# StarFive VisionFive 2 v1.3B register map
File version: 0.1
Registers are 32-bit, read-write, reset 0x0 unless marked. A register's access mark holds for its fields unless they carry their own. Offsets are from the block's base; [hi:lo] are bit positions; {n}, {i} and the like mark numbered series; 'fields as' and 'values as' point back to an identical list.

## sys_pinctrl — From starfive,jh7110-sys-pinctrl, peripheral generator
Base 0x13040000
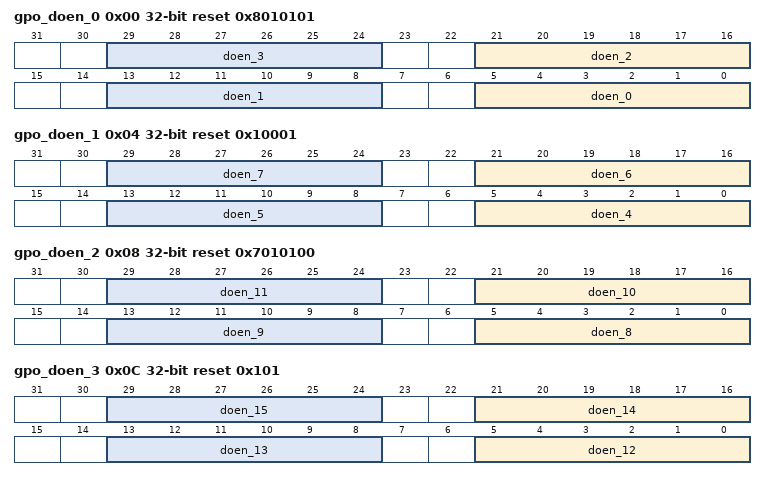
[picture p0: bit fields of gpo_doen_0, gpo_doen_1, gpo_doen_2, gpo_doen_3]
0x00 gpo_doen_0 reset 0x8010101 — SYS IOMUX CFG SAIF SYSCFG FMUX 0 DOEN
  [8n+5:8n] doen_{n} (n=0..3) — The selected OEN signal for GPIO{n}. The register value indicates the selected GPIO (Output Enable) OEN index from GPIO OEN list 0-49. See Table 2-41: GPIO OEN List for SYS_IOMUX (on page 97) for more information.
0x04 gpo_doen_1 reset 0x10001 — SYS IOMUX CFG SAIF SYSCFG FMUX 1 DOEN
  [8n-27:8n-32] doen_{n} (n=4..7) — The selected OEN signal for GPIO{n}. The register value indicates the selected GPIO (Output Enable) OEN index from GPIO OEN list 0-49. See Table 2-41: GPIO OEN List for SYS_IOMUX (on page 97) for more information.
0x08 gpo_doen_2 reset 0x7010100 — SYS IOMUX CFG SAIF SYSCFG FMUX 2 DOEN
  [8n-59:8n-64] doen_{n} (n=8..11) — The selected OEN signal for GPIO{n}. The register value indicates the selected GPIO (Output Enable) OEN index from GPIO OEN list 0-49. See Table 2-41: GPIO OEN List for SYS_IOMUX (on page 97) for more information.
0x0C gpo_doen_3 reset 0x101 — SYS IOMUX CFG SAIF SYSCFG FMUX 3 DOEN
  [8n-91:8n-96] doen_{n} (n=12..15) — The selected OEN signal for GPIO{n}. The register value indicates the selected GPIO (Output Enable) OEN index from GPIO OEN list 0-49. See Table 2-41: GPIO OEN List for SYS_IOMUX (on page 97) for more information.
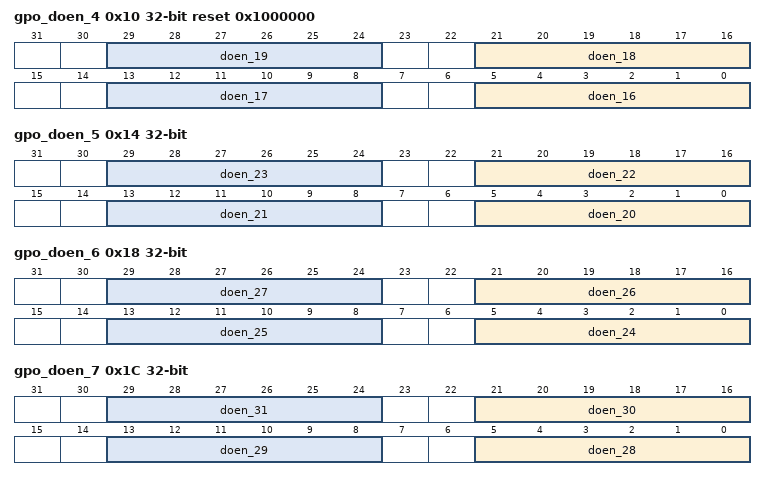
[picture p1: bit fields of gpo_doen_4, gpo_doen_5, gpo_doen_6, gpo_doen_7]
0x10 gpo_doen_4 reset 0x1000000 — SYS IOMUX CFG SAIF SYSCFG FMUX 4 DOEN
  [8n-123:8n-128] doen_{n} (n=16..19) — The selected OEN signal for GPIO{n}. The register value indicates the selected GPIO (Output Enable) OEN index from GPIO OEN list 0-49. See Table 2-41: GPIO OEN List for SYS_IOMUX (on page 97) for more information.
0x14 gpo_doen_5 — SYS IOMUX CFG SAIF SYSCFG FMUX 5 DOEN
  [8n-155:8n-160] doen_{n} (n=20..23) — The selected OEN signal for GPIO{n}. The register value indicates the selected GPIO (Output Enable) OEN index from GPIO OEN list 0-49. See Table 2-41: GPIO OEN List for SYS_IOMUX (on page 97) for more information.
0x18 gpo_doen_6 — SYS IOMUX CFG SAIF SYSCFG FMUX 6 DOEN
  [8n-187:8n-192] doen_{n} (n=24..27) — The selected OEN signal for GPIO{n}. The register value indicates the selected GPIO (Output Enable) OEN index from GPIO OEN list 0-49. See Table 2-41: GPIO OEN List for SYS_IOMUX (on page 97) for more information.
0x1C gpo_doen_7 — SYS IOMUX CFG SAIF SYSCFG FMUX 7 DOEN
  [8n-219:8n-224] doen_{n} (n=28..31) — The selected OEN signal for GPIO{n}. The register value indicates the selected GPIO (Output Enable) OEN index from GPIO OEN list 0-49. See Table 2-41: GPIO OEN List for SYS_IOMUX (on page 97) for more information.
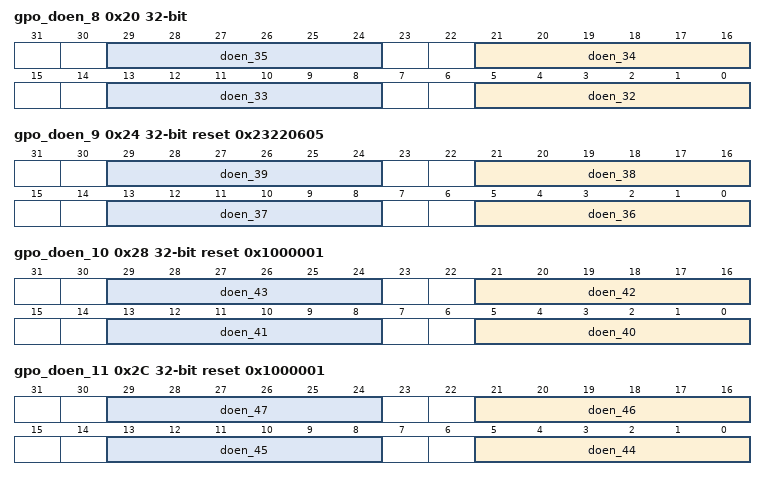
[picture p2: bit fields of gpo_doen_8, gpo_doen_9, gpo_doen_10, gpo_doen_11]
0x20 gpo_doen_8 — SYS IOMUX CFG SAIF SYSCFG FMUX 8 DOEN
  [8n-251:8n-256] doen_{n} (n=32..35) — The selected OEN signal for GPIO{n}. The register value indicates the selected GPIO (Output Enable) OEN index from GPIO OEN list 0-49. See Table 2-41: GPIO OEN List for SYS_IOMUX (on page 97) for more information.
0x24 gpo_doen_9 reset 0x23220605 — SYS IOMUX CFG SAIF SYSCFG FMUX 9 DOEN
  [8n-283:8n-288] doen_{n} (n=36..39) — The selected OEN signal for GPIO{n}. The register value indicates the selected GPIO (Output Enable) OEN index from GPIO OEN list 0-49. See Table 2-41: GPIO OEN List for SYS_IOMUX (on page 97) for more information.
0x28 gpo_doen_10 reset 0x1000001 — SYS IOMUX CFG SAIF SYSCFG FMUX 10 DOEN
  [8n-315:8n-320] doen_{n} (n=40..43) — The selected OEN signal for GPIO{n}. The register value indicates the selected GPIO (Output Enable) OEN index from GPIO OEN list 0-49. See Table 2-41: GPIO OEN List for SYS_IOMUX (on page 97) for more information.
0x2C gpo_doen_11 reset 0x1000001 — SYS IOMUX CFG SAIF SYSCFG FMUX 11 DOEN
  [8n-347:8n-352] doen_{n} (n=44..47) — The selected OEN signal for GPIO{n}. The register value indicates the selected GPIO (Output Enable) OEN index from GPIO OEN list 0-49. See Table 2-41: GPIO OEN List for SYS_IOMUX (on page 97) for more information.
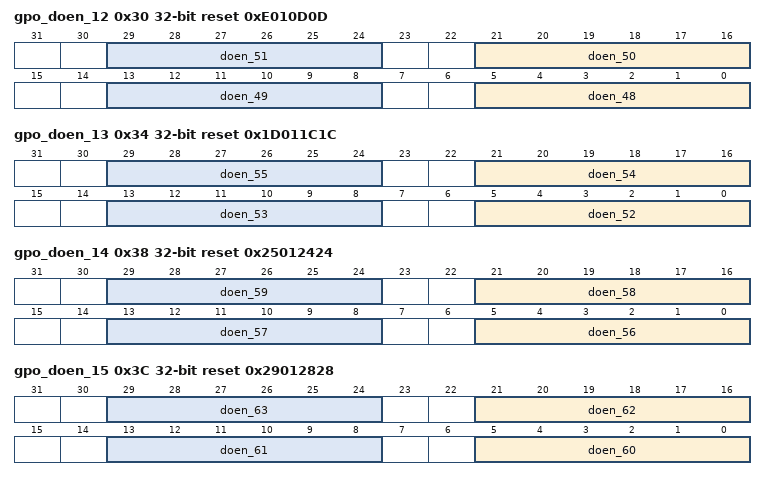
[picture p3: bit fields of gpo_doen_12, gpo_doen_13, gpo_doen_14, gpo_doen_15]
0x30 gpo_doen_12 reset 0xE010D0D — SYS IOMUX CFG SAIF SYSCFG FMUX 12 DOEN
  [8n-379:8n-384] doen_{n} (n=48..51) — The selected OEN signal for GPIO{n}. The register value indicates the selected GPIO (Output Enable) OEN index from GPIO OEN list 0-49. See Table 2-41: GPIO OEN List for SYS_IOMUX (on page 97) for more information.
0x34 gpo_doen_13 reset 0x1D011C1C — SYS IOMUX CFG SAIF SYSCFG FMUX 13 DOEN
  [8n-411:8n-416] doen_{n} (n=52..55) — The selected OEN signal for GPIO{n}. The register value indicates the selected GPIO (Output Enable) OEN index from GPIO OEN list 0-49. See Table 2-41: GPIO OEN List for SYS_IOMUX (on page 97) for more information.
0x38 gpo_doen_14 reset 0x25012424 — SYS IOMUX CFG SAIF SYSCFG FMUX 14 DOEN
  [8n-443:8n-448] doen_{n} (n=56..59) — The selected OEN signal for GPIO{n}. The register value indicates the selected GPIO (Output Enable) OEN index from GPIO OEN list 0-49. See Table 2-41: GPIO OEN List for SYS_IOMUX (on page 97) for more information.
0x3C gpo_doen_15 reset 0x29012828 — SYS IOMUX CFG SAIF SYSCFG FMUX 15 DOEN
  [8n-475:8n-480] doen_{n} (n=60..63) — The selected OEN signal for GPIO{n}. The register value indicates the selected GPIO (Output Enable) OEN index from GPIO OEN list 0-49. See Table 2-41: GPIO OEN List for SYS_IOMUX (on page 97) for more information.
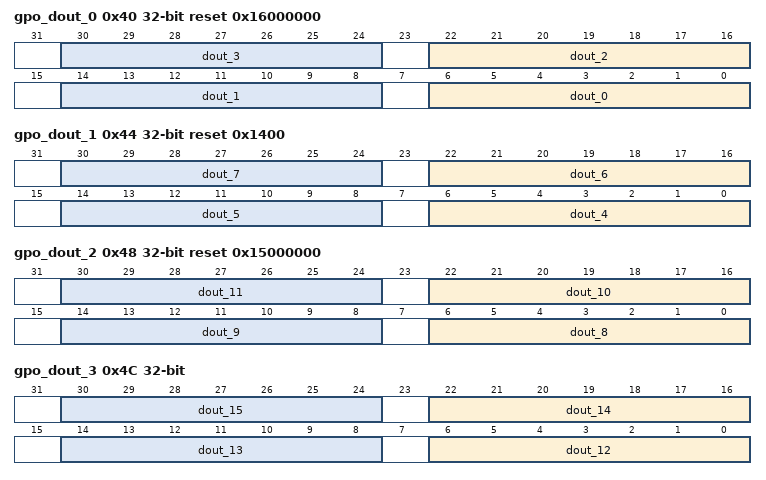
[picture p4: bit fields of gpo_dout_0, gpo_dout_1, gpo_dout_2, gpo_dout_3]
0x40 gpo_dout_0 reset 0x16000000 — SYS IOMUX CFG SAIF SYSCFG FMUX GPIO 0-3 DOUT
  [8n+6:8n] dout_{n} (n=0..3) — The selected output signal for GPIO{n}. The register value indicates the selected GPIO output index signal index from GPIO output signal list 0-107. See Table 2-41: GPIO OEN List for SYS_IOMUX (on page 97) for more information.
0x44 gpo_dout_1 reset 0x1400 — SYS IOMUX CFG SAIF SYSCFG FMUX GPIO 4-7 DOUT
  [8n-26:8n-32] dout_{n} (n=4..7) — The selected output signal for GPIO{n}. The register value indicates the selected GPIO output index signal index from GPIO output signal list 0-107. See Table 2-41: GPIO OEN List for SYS_IOMUX (on page 97) for more information.
0x48 gpo_dout_2 reset 0x15000000 — SYS IOMUX CFG SAIF SYSCFG FMUX GPIO 8-11 DOUT
  [8n-58:8n-64] dout_{n} (n=8..11) — The selected output signal for GPIO{n}. The register value indicates the selected GPIO output index signal index from GPIO output signal list 0-107. See Table 2-41: GPIO OEN List for SYS_IOMUX (on page 97) for more information.
0x4C gpo_dout_3 — SYS IOMUX CFG SAIF SYSCFG FMUX GPIO 12-15 DOUT
  [8n-90:8n-96] dout_{n} (n=12..15) — The selected output signal for GPIO{n}. The register value indicates the selected GPIO output index signal index from GPIO output signal list 0-107. See Table 2-41: GPIO OEN List for SYS_IOMUX (on page 97) for more information.
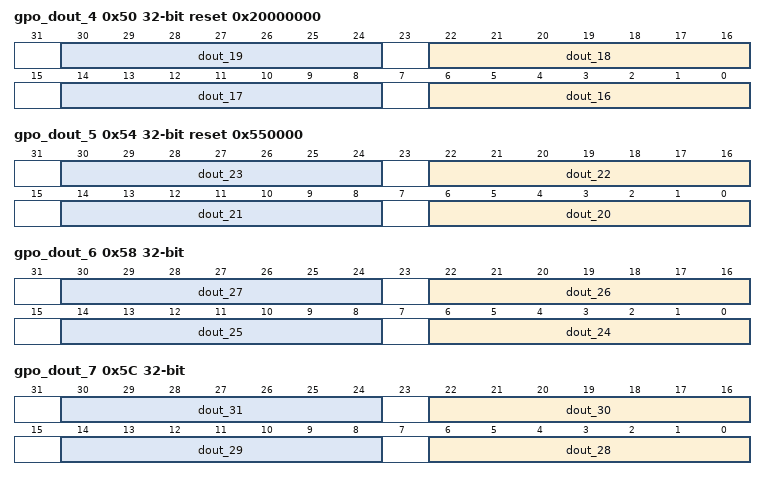
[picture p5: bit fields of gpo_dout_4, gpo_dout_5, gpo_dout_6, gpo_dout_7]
0x50 gpo_dout_4 reset 0x20000000 — SYS IOMUX CFG SAIF SYSCFG FMUX GPIO 16-19 DOUT
  [8n-122:8n-128] dout_{n} (n=16..19) — The selected output signal for GPIO{n}. The register value indicates the selected GPIO output index signal index from GPIO output signal list 0-107. See Table 2-41: GPIO OEN List for SYS_IOMUX (on page 97) for more information.
0x54 gpo_dout_5 reset 0x550000 — SYS IOMUX CFG SAIF SYSCFG FMUX GPIO 20-23 DOUT
  [8n-154:8n-160] dout_{n} (n=20..23) — The selected output signal for GPIO{n}. The register value indicates the selected GPIO output index signal index from GPIO output signal list 0-107. See Table 2-41: GPIO OEN List for SYS_IOMUX (on page 97) for more information.
0x58 gpo_dout_6 — SYS IOMUX CFG SAIF SYSCFG FMUX GPIO 24-27 DOUT
  [8n-186:8n-192] dout_{n} (n=24..27) — The selected output signal for GPIO{n}. The register value indicates the selected GPIO output index signal index from GPIO output signal list 0-107. See Table 2-41: GPIO OEN List for SYS_IOMUX (on page 97) for more information.
0x5C gpo_dout_7 — SYS IOMUX CFG SAIF SYSCFG FMUX GPIO 28-31 DOUT
  [8n-218:8n-224] dout_{n} (n=28..31) — The selected output signal for GPIO{n}. The register value indicates the selected GPIO output index signal index from GPIO output signal list 0-107. See Table 2-41: GPIO OEN List for SYS_IOMUX (on page 97) for more information.
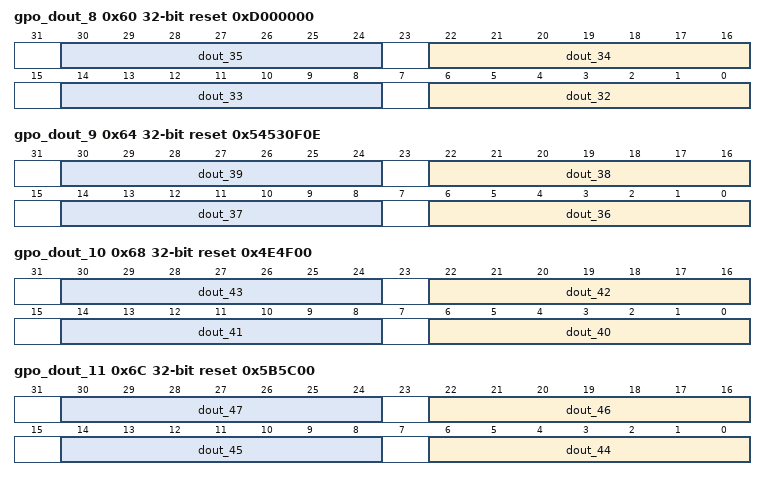
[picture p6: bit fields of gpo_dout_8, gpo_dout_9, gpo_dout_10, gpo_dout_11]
0x60 gpo_dout_8 reset 0xD000000 — SYS IOMUX CFG SAIF SYSCFG FMUX GPIO 32-35 DOUT
  [8n-250:8n-256] dout_{n} (n=32..35) — The selected output signal for GPIO{n}. The register value indicates the selected GPIO output index signal index from GPIO output signal list 0-107. See Table 2-41: GPIO OEN List for SYS_IOMUX (on page 97) for more information.
0x64 gpo_dout_9 reset 0x54530F0E — SYS IOMUX CFG SAIF SYSCFG FMUX GPIO 36-39 DOUT
  [8n-282:8n-288] dout_{n} (n=36..39) — The selected output signal for GPIO{n}. The register value indicates the selected GPIO output index signal index from GPIO output signal list 0-107. See Table 2-41: GPIO OEN List for SYS_IOMUX (on page 97) for more information.
0x68 gpo_dout_10 reset 0x4E4F00 — SYS IOMUX CFG SAIF SYSCFG FMUX GPIO 40-43 DOUT
  [8n-314:8n-320] dout_{n} (n=40..43) — The selected output signal for GPIO{n}. The register value indicates the selected GPIO output index signal index from GPIO output signal list 0-107. See Table 2-41: GPIO OEN List for SYS_IOMUX (on page 97) for more information.
0x6C gpo_dout_11 reset 0x5B5C00 — SYS IOMUX CFG SAIF SYSCFG FMUX GPIO 44-47 DOUT
  [8n-346:8n-352] dout_{n} (n=44..47) — The selected output signal for GPIO{n}. The register value indicates the selected GPIO output index signal index from GPIO output signal list 0-107. See Table 2-41: GPIO OEN List for SYS_IOMUX (on page 97) for more information.
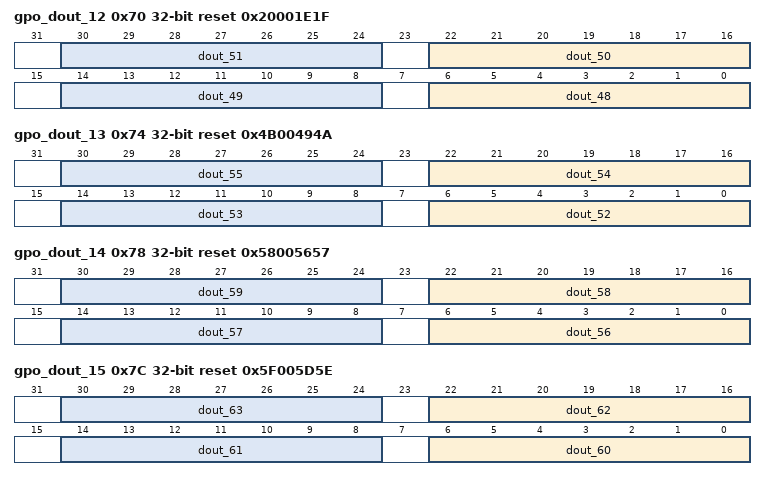
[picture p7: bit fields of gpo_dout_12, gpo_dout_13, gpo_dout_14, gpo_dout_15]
0x70 gpo_dout_12 reset 0x20001E1F — SYS IOMUX CFG SAIF SYSCFG FMUX GPIO 48-51 DOUT
  [8n-378:8n-384] dout_{n} (n=48..51) — The selected output signal for GPIO{n}. The register value indicates the selected GPIO output index signal index from GPIO output signal list 0-107. See Table 2-41: GPIO OEN List for SYS_IOMUX (on page 97) for more information.
0x74 gpo_dout_13 reset 0x4B00494A — SYS IOMUX CFG SAIF SYSCFG FMUX GPIO 52-55 DOUT
  [8n-410:8n-416] dout_{n} (n=52..55) — The selected output signal for GPIO{n}. The register value indicates the selected GPIO output index signal index from GPIO output signal list 0-107. See Table 2-41: GPIO OEN List for SYS_IOMUX (on page 97) for more information.
0x78 gpo_dout_14 reset 0x58005657 — SYS IOMUX CFG SAIF SYSCFG FMUX GPIO 56-59 DOUT
  [8n-442:8n-448] dout_{n} (n=56..59) — The selected output signal for GPIO{n}. The register value indicates the selected GPIO output index signal index from GPIO output signal list 0-107. See Table 2-41: GPIO OEN List for SYS_IOMUX (on page 97) for more information.
0x7C gpo_dout_15 reset 0x5F005D5E — SYS IOMUX CFG SAIF SYSCFG FMUX GPIO 60-63 DOUT
  [8n-474:8n-480] dout_{n} (n=60..63) — The selected output signal for GPIO{n}. The register value indicates the selected GPIO output index signal index from GPIO output signal list 0-107. See Table 2-41: GPIO OEN List for SYS_IOMUX (on page 97) for more information.
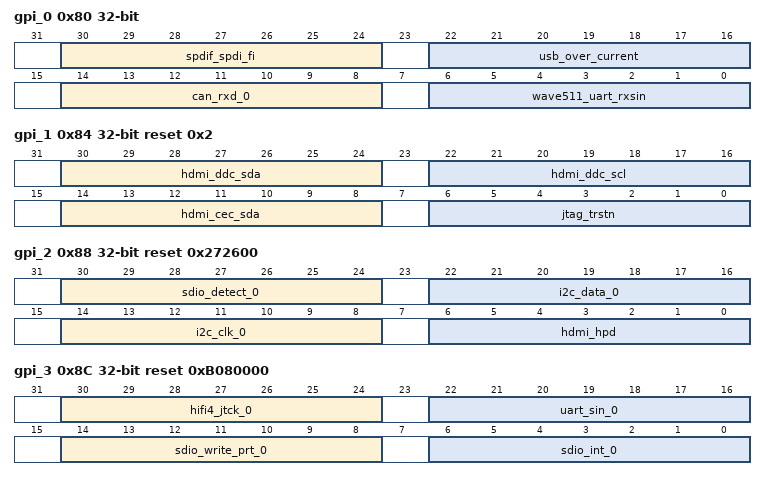
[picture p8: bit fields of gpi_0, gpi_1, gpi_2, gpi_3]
0x80 gpi_0 — SYS IOMUX CFG SAIF SYSCFG FMUX GPIO GPI 0 - The register can be used to configure the selected GPIO connector number for input signals. The signal name is indicated in the "Name" column of the following table per StarFive naming conventions. For example, name "u0_WAVE511_i_uart_rxsin_cfg" indicates the corresponding input signal is "u0_WAVE511.i_uart_rxsin". See GPIO Input Signals (on page 107) for a complete list of the input GPIO signals.
  [30:24] spdif_spdi_fi — The register value indicates the selected GPIO number + 2 (GPIO2 - GPIO63, GPIO0 and GPIO1 are not available) for the input signal.
  [22:16] usb_over_current — The register value indicates the selected GPIO number + 2 (GPIO2 - GPIO63, GPIO0 and GPIO1 are not available) for the input signal.
  [14:8] can_rxd_0 — The register value indicates the selected GPIO number + 2 (GPIO2 - GPIO63, GPIO0 and GPIO1 are not available) for the input signal.
  [6:0] wave511_uart_rxsin — The register value indicates the selected GPIO number + 2 (GPIO2 - GPIO63, GPIO0 and GPIO1 are not available) for the input signal.
0x84 gpi_1 reset 0x2 — SYS IOMUX CFG SAIF SYSCFG FMUX GPIO GPI 4 - The register can be used to configure the selected GPIO connector number for input signals. The signal name is indicated in the "Name" column of the following table per StarFive naming conventions. For example, name "u0_WAVE511_i_uart_rxsin_cfg" indicates the corresponding input signal is "u0_WAVE511.i_uart_rxsin". See GPIO Input Signals (on page 107) for a complete list of the input GPIO signals.
  [30:24] hdmi_ddc_sda — The register value indicates the selected GPIO number + 2 (GPIO2 - GPIO63, GPIO0 and GPIO1 are not available) for the input signal.
  [22:16] hdmi_ddc_scl — The register value indicates the selected GPIO number + 2 (GPIO2 - GPIO63, GPIO0 and GPIO1 are not available) for the input signal.
  [14:8] hdmi_cec_sda — The register value indicates the selected GPIO number + 2 (GPIO2 - GPIO63, GPIO0 and GPIO1 are not available) for the input signal.
  [6:0] jtag_trstn — The register value indicates the selected GPIO number + 2 (GPIO2 - GPIO63, GPIO0 and GPIO1 are not available) for the input signal.
0x88 gpi_2 reset 0x272600 — SYS IOMUX CFG SAIF SYSCFG FMUX GPIO GPI 8 - The register can be used to configure the selected GPIO connector number for input signals. The signal name is indicated in the "Name" column of the following table per StarFive naming conventions. For example, name "u0_WAVE511_i_uart_rxsin_cfg" indicates the corresponding input signal is "u0_WAVE511.i_uart_rxsin". See GPIO Input Signals (on page 107) for a complete list of the input GPIO signals.
  [30:24] sdio_detect_0 — The register value indicates the selected GPIO number + 2 (GPIO2 - GPIO63, GPIO0 and GPIO1 are not available) for the input signal.
  [22:16] i2c_data_0 — The register value indicates the selected GPIO number + 2 (GPIO2 - GPIO63, GPIO0 and GPIO1 are not available) for the input signal.
  [14:8] i2c_clk_0 — The register value indicates the selected GPIO number + 2 (GPIO2 - GPIO63, GPIO0 and GPIO1 are not available) for the input signal.
  [6:0] hdmi_hpd — The register value indicates the selected GPIO number + 2 (GPIO2 - GPIO63, GPIO0 and GPIO1 are not available) for the input signal.
0x8C gpi_3 reset 0xB080000 — SYS IOMUX CFG SAIF SYSCFG FMUX GPIO GPI 12 - The register can be used to configure the selected GPIO connector number for input signals. The signal name is indicated in the "Name" column of the following table per StarFive naming conventions. For example, name "u0_WAVE511_i_uart_rxsin_cfg" indicates the corresponding input signal is "u0_WAVE511.i_uart_rxsin". See GPIO Input Signals (on page 107) for a complete list of the input GPIO signals.
  [30:24] hifi4_jtck_0 — The register value indicates the selected GPIO number + 2 (GPIO2 - GPIO63, GPIO0 and GPIO1 are not available) for the input signal.
  [22:16] uart_sin_0 — The register value indicates the selected GPIO number + 2 (GPIO2 - GPIO63, GPIO0 and GPIO1 are not available) for the input signal.
  [14:8] sdio_write_prt_0 — The register value indicates the selected GPIO number + 2 (GPIO2 - GPIO63, GPIO0 and GPIO1 are not available) for the input signal.
  [6:0] sdio_int_0 — The register value indicates the selected GPIO number + 2 (GPIO2 - GPIO63, GPIO0 and GPIO1 are not available) for the input signal.
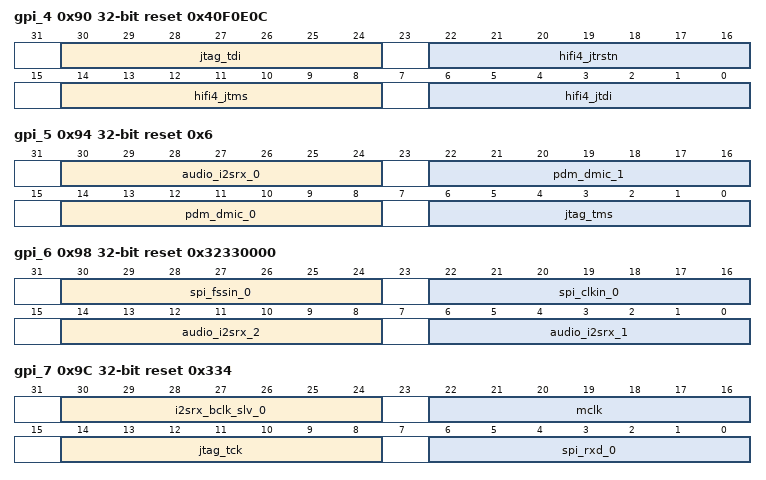
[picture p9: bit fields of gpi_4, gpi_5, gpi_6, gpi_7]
0x90 gpi_4 reset 0x40F0E0C — SYS IOMUX CFG SAIF SYSCFG FMUX GPIO GPI 16 - The register can be used to configure the selected GPIO connector number for input signals. The signal name is indicated in the "Name" column of the following table per StarFive naming conventions. For example, name "u0_WAVE511_i_uart_rxsin_cfg" indicates the corresponding input signal is "u0_WAVE511.i_uart_rxsin". See GPIO Input Signals (on page 107) for a complete list of the input GPIO signals.
  [30:24] jtag_tdi — The register value indicates the selected GPIO number + 2 (GPIO2 - GPIO63, GPIO0 and GPIO1 are not available) for the input signal.
  [22:16] hifi4_jtrstn — The register value indicates the selected GPIO number + 2 (GPIO2 - GPIO63, GPIO0 and GPIO1 are not available) for the input signal.
  [14:8] hifi4_jtms — The register value indicates the selected GPIO number + 2 (GPIO2 - GPIO63, GPIO0 and GPIO1 are not available) for the input signal.
  [6:0] hifi4_jtdi — The register value indicates the selected GPIO number + 2 (GPIO2 - GPIO63, GPIO0 and GPIO1 are not available) for the input signal.
0x94 gpi_5 reset 0x6 — SYS IOMUX CFG SAIF SYSCFG FMUX GPIO GPI 20 - The register can be used to configure the selected GPIO connector number for input signals. The signal name is indicated in the "Name" column of the following table per StarFive naming conventions. For example, name "u0_WAVE511_i_uart_rxsin_cfg" indicates the corresponding input signal is "u0_WAVE511.i_uart_rxsin". See GPIO Input Signals (on page 107) for a complete list of the input GPIO signals.
  [30:24] audio_i2srx_0 — The register value indicates the selected GPIO number + 2 (GPIO2 - GPIO63, GPIO0 and GPIO1 are not available) for the input signal.
  [22:16] pdm_dmic_1 — The register value indicates the selected GPIO number + 2 (GPIO2 - GPIO63, GPIO0 and GPIO1 are not available) for the input signal.
  [14:8] pdm_dmic_0 — The register value indicates the selected GPIO number + 2 (GPIO2 - GPIO63, GPIO0 and GPIO1 are not available) for the input signal.
  [6:0] jtag_tms — The register value indicates the selected GPIO number + 2 (GPIO2 - GPIO63, GPIO0 and GPIO1 are not available) for the input signal.
0x98 gpi_6 reset 0x32330000 — SYS IOMUX CFG SAIF SYSCFG FMUX GPIO GPI 24 - The register can be used to configure the selected GPIO connector number for input signals. The signal name is indicated in the "Name" column of the following table per StarFive naming conventions. For example, name "u0_WAVE511_i_uart_rxsin_cfg" indicates the corresponding input signal is "u0_WAVE511.i_uart_rxsin". See GPIO Input Signals (on page 107) for a complete list of the input GPIO signals.
  [30:24] spi_fssin_0 — The register value indicates the selected GPIO number + 2 (GPIO2 - GPIO63, GPIO0 and GPIO1 are not available) for the input signal.
  [22:16] spi_clkin_0 — The register value indicates the selected GPIO number + 2 (GPIO2 - GPIO63, GPIO0 and GPIO1 are not available) for the input signal.
  [14:8] audio_i2srx_2 — The register value indicates the selected GPIO number + 2 (GPIO2 - GPIO63, GPIO0 and GPIO1 are not available) for the input signal.
  [6:0] audio_i2srx_1 — The register value indicates the selected GPIO number + 2 (GPIO2 - GPIO63, GPIO0 and GPIO1 are not available) for the input signal.
0x9C gpi_7 reset 0x334 — SYS IOMUX CFG SAIF SYSCFG FMUX GPIO GPI 28 - The register can be used to configure the selected GPIO connector number for input signals. The signal name is indicated in the "Name" column of the following table per StarFive naming conventions. For example, name "u0_WAVE511_i_uart_rxsin_cfg" indicates the corresponding input signal is "u0_WAVE511.i_uart_rxsin". See GPIO Input Signals (on page 107) for a complete list of the input GPIO signals.
  [30:24] i2srx_bclk_slv_0 — The register value indicates the selected GPIO number + 2 (GPIO2 - GPIO63, GPIO0 and GPIO1 are not available) for the input signal.
  [22:16] mclk — The register value indicates the selected GPIO number + 2 (GPIO2 - GPIO63, GPIO0 and GPIO1 are not available) for the input signal.
  [14:8] jtag_tck — The register value indicates the selected GPIO number + 2 (GPIO2 - GPIO63, GPIO0 and GPIO1 are not available) for the input signal.
  [6:0] spi_rxd_0 — The register value indicates the selected GPIO number + 2 (GPIO2 - GPIO63, GPIO0 and GPIO1 are not available) for the input signal.
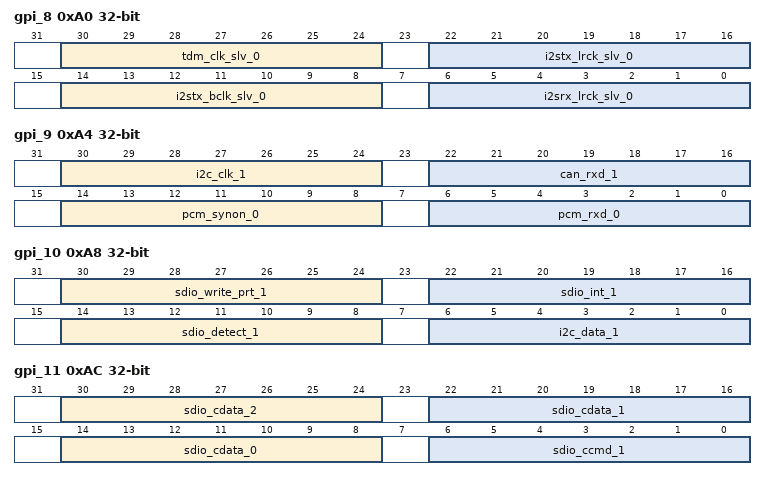
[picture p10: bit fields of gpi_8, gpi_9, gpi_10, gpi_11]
0xA0 gpi_8 — SYS IOMUX CFG SAIF SYSCFG FMUX GPIO GPI 32 - The register can be used to configure the selected GPIO connector number for input signals. The signal name is indicated in the "Name" column of the following table per StarFive naming conventions. For example, name "u0_WAVE511_i_uart_rxsin_cfg" indicates the corresponding input signal is "u0_WAVE511.i_uart_rxsin". See GPIO Input Signals (on page 107) for a complete list of the input GPIO signals.
  [30:24] tdm_clk_slv_0 — The register value indicates the selected GPIO number + 2 (GPIO2 - GPIO63, GPIO0 and GPIO1 are not available) for the input signal.
  [22:16] i2stx_lrck_slv_0 — The register value indicates the selected GPIO number + 2 (GPIO2 - GPIO63, GPIO0 and GPIO1 are not available) for the input signal.
  [14:8] i2stx_bclk_slv_0 — The register value indicates the selected GPIO number + 2 (GPIO2 - GPIO63, GPIO0 and GPIO1 are not available) for the input signal.
  [6:0] i2srx_lrck_slv_0 — The register value indicates the selected GPIO number + 2 (GPIO2 - GPIO63, GPIO0 and GPIO1 are not available) for the input signal.
0xA4 gpi_9 — SYS IOMUX CFG SAIF SYSCFG FMUX GPIO GPI 36 - The register can be used to configure the selected GPIO connector number for input signals. The signal name is indicated in the "Name" column of the following table per StarFive naming conventions. For example, name "u0_WAVE511_i_uart_rxsin_cfg" indicates the corresponding input signal is "u0_WAVE511.i_uart_rxsin". See GPIO Input Signals (on page 107) for a complete list of the input GPIO signals.
  [30:24] i2c_clk_1 — The register value indicates the selected GPIO number + 2 (GPIO2 - GPIO63, GPIO0 and GPIO1 are not available) for the input signal.
  [22:16] can_rxd_1 — The register value indicates the selected GPIO number + 2 (GPIO2 - GPIO63, GPIO0 and GPIO1 are not available) for the input signal.
  [14:8] pcm_synon_0 — The register value indicates the selected GPIO number + 2 (GPIO2 - GPIO63, GPIO0 and GPIO1 are not available) for the input signal.
  [6:0] pcm_rxd_0 — The register value indicates the selected GPIO number + 2 (GPIO2 - GPIO63, GPIO0 and GPIO1 are not available) for the input signal.
0xA8 gpi_10 — SYS IOMUX CFG SAIF SYSCFG FMUX GPIO GPI 40 - The register can be used to configure the selected GPIO connector number for input signals. The signal name is indicated in the "Name" column of the following table per StarFive naming conventions. For example, name "u0_WAVE511_i_uart_rxsin_cfg" indicates the corresponding input signal is "u0_WAVE511.i_uart_rxsin". See GPIO Input Signals (on page 107) for a complete list of the input GPIO signals.
  [30:24] sdio_write_prt_1 — The register value indicates the selected GPIO number + 2 (GPIO2 - GPIO63, GPIO0 and GPIO1 are not available) for the input signal.
  [22:16] sdio_int_1 — The register value indicates the selected GPIO number + 2 (GPIO2 - GPIO63, GPIO0 and GPIO1 are not available) for the input signal.
  [14:8] sdio_detect_1 — The register value indicates the selected GPIO number + 2 (GPIO2 - GPIO63, GPIO0 and GPIO1 are not available) for the input signal.
  [6:0] i2c_data_1 — The register value indicates the selected GPIO number + 2 (GPIO2 - GPIO63, GPIO0 and GPIO1 are not available) for the input signal.
0xAC gpi_11 — SYS IOMUX CFG SAIF SYSCFG FMUX GPIO GPI 44 - The register can be used to configure the selected GPIO connector number for input signals. The signal name is indicated in the "Name" column of the following table per StarFive naming conventions. For example, name "u0_WAVE511_i_uart_rxsin_cfg" indicates the corresponding input signal is "u0_WAVE511.i_uart_rxsin". See GPIO Input Signals (on page 107) for a complete list of the input GPIO signals.
  [30:24] sdio_cdata_2 — The register value indicates the selected GPIO number + 2 (GPIO2 - GPIO63, GPIO0 and GPIO1 are not available) for the input signal.
  [22:16] sdio_cdata_1 — The register value indicates the selected GPIO number + 2 (GPIO2 - GPIO63, GPIO0 and GPIO1 are not available) for the input signal.
  [14:8] sdio_cdata_0 — The register value indicates the selected GPIO number + 2 (GPIO2 - GPIO63, GPIO0 and GPIO1 are not available) for the input signal.
  [6:0] sdio_ccmd_1 — The register value indicates the selected GPIO number + 2 (GPIO2 - GPIO63, GPIO0 and GPIO1 are not available) for the input signal.
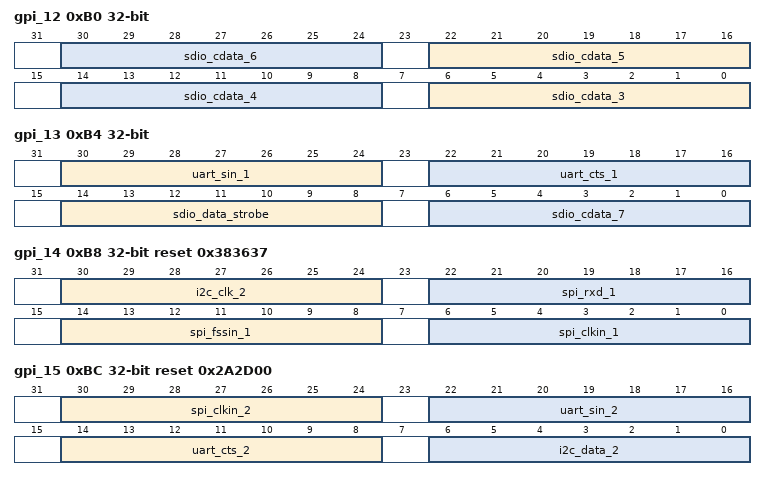
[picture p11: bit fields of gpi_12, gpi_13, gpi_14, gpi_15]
0xB0 gpi_12 — SYS IOMUX CFG SAIF SYSCFG FMUX GPIO GPI 48 - The register can be used to configure the selected GPIO connector number for input signals. The signal name is indicated in the "Name" column of the following table per StarFive naming conventions. For example, name "u0_WAVE511_i_uart_rxsin_cfg" indicates the corresponding input signal is "u0_WAVE511.i_uart_rxsin". See GPIO Input Signals (on page 107) for a complete list of the input GPIO signals.
  [8n-18:8n-24] sdio_cdata_{n} (n=3..6) — The register value indicates the selected GPIO number + 2 (GPIO2 - GPIO63, GPIO0 and GPIO1 are not available) for the input signal.
0xB4 gpi_13 — SYS IOMUX CFG SAIF SYSCFG FMUX GPIO GPI 52 - The register can be used to configure the selected GPIO connector number for input signals. The signal name is indicated in the "Name" column of the following table per StarFive naming conventions. For example, name "u0_WAVE511_i_uart_rxsin_cfg" indicates the corresponding input signal is "u0_WAVE511.i_uart_rxsin". See GPIO Input Signals (on page 107) for a complete list of the input GPIO signals.
  [30:24] uart_sin_1 — The register value indicates the selected GPIO number + 2 (GPIO2 - GPIO63, GPIO0 and GPIO1 are not available) for the input signal.
  [22:16] uart_cts_1 — The register value indicates the selected GPIO number + 2 (GPIO2 - GPIO63, GPIO0 and GPIO1 are not available) for the input signal.
  [14:8] sdio_data_strobe — The register value indicates the selected GPIO number + 2 (GPIO2 - GPIO63, GPIO0 and GPIO1 are not available) for the input signal.
  [6:0] sdio_cdata_7 — The register value indicates the selected GPIO number + 2 (GPIO2 - GPIO63, GPIO0 and GPIO1 are not available) for the input signal.
0xB8 gpi_14 reset 0x383637 — SYS IOMUX CFG SAIF SYSCFG FMUX GPIO GPI 56 - The register can be used to configure the selected GPIO connector number for input signals. The signal name is indicated in the "Name" column of the following table per StarFive naming conventions. For example, name "u0_WAVE511_i_uart_rxsin_cfg" indicates the corresponding input signal is "u0_WAVE511.i_uart_rxsin". See GPIO Input Signals (on page 107) for a complete list of the input GPIO signals.
  [30:24] i2c_clk_2 — The register value indicates the selected GPIO number + 2 (GPIO2 - GPIO63, GPIO0 and GPIO1 are not available) for the input signal.
  [22:16] spi_rxd_1 — The register value indicates the selected GPIO number + 2 (GPIO2 - GPIO63, GPIO0 and GPIO1 are not available) for the input signal.
  [14:8] spi_fssin_1 — The register value indicates the selected GPIO number + 2 (GPIO2 - GPIO63, GPIO0 and GPIO1 are not available) for the input signal.
  [6:0] spi_clkin_1 — The register value indicates the selected GPIO number + 2 (GPIO2 - GPIO63, GPIO0 and GPIO1 are not available) for the input signal.
0xBC gpi_15 reset 0x2A2D00 — SYS IOMUX CFG SAIF SYSCFG FMUX GPIO GPI 60 - The register can be used to configure the selected GPIO connector number for input signals. The signal name is indicated in the "Name" column of the following table per StarFive naming conventions. For example, name "u0_WAVE511_i_uart_rxsin_cfg" indicates the corresponding input signal is "u0_WAVE511.i_uart_rxsin". See GPIO Input Signals (on page 107) for a complete list of the input GPIO signals.
  [30:24] spi_clkin_2 — The register value indicates the selected GPIO number + 2 (GPIO2 - GPIO63, GPIO0 and GPIO1 are not available) for the input signal.
  [22:16] uart_sin_2 — The register value indicates the selected GPIO number + 2 (GPIO2 - GPIO63, GPIO0 and GPIO1 are not available) for the input signal.
  [14:8] uart_cts_2 — The register value indicates the selected GPIO number + 2 (GPIO2 - GPIO63, GPIO0 and GPIO1 are not available) for the input signal.
  [6:0] i2c_data_2 — The register value indicates the selected GPIO number + 2 (GPIO2 - GPIO63, GPIO0 and GPIO1 are not available) for the input signal.
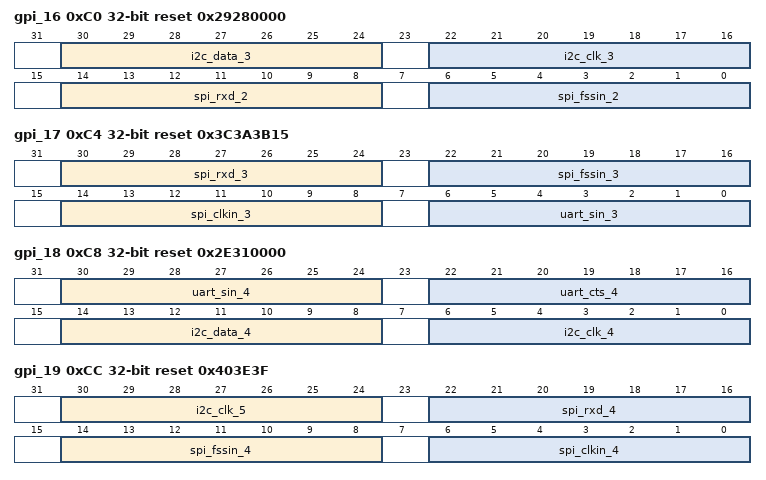
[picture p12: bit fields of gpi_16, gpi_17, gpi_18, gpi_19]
0xC0 gpi_16 reset 0x29280000 — SYS IOMUX CFG SAIF SYSCFG FMUX GPIO GPI 64 - The register can be used to configure the selected GPIO connector number for input signals. The signal name is indicated in the "Name" column of the following table per StarFive naming conventions. For example, name "u0_WAVE511_i_uart_rxsin_cfg" indicates the corresponding input signal is "u0_WAVE511.i_uart_rxsin". See GPIO Input Signals (on page 107) for a complete list of the input GPIO signals.
  [30:24] i2c_data_3 — The register value indicates the selected GPIO number + 2 (GPIO2 - GPIO63, GPIO0 and GPIO1 are not available) for the input signal.
  [22:16] i2c_clk_3 — The register value indicates the selected GPIO number + 2 (GPIO2 - GPIO63, GPIO0 and GPIO1 are not available) for the input signal.
  [14:8] spi_rxd_2 — The register value indicates the selected GPIO number + 2 (GPIO2 - GPIO63, GPIO0 and GPIO1 are not available) for the input signal.
  [6:0] spi_fssin_2 — The register value indicates the selected GPIO number + 2 (GPIO2 - GPIO63, GPIO0 and GPIO1 are not available) for the input signal.
0xC4 gpi_17 reset 0x3C3A3B15 — SYS IOMUX CFG SAIF SYSCFG FMUX GPIO GPI 68 - The register can be used to configure the selected GPIO connector number for input signals. The signal name is indicated in the "Name" column of the following table per StarFive naming conventions. For example, name "u0_WAVE511_i_uart_rxsin_cfg" indicates the corresponding input signal is "u0_WAVE511.i_uart_rxsin". See GPIO Input Signals (on page 107) for a complete list of the input GPIO signals.
  [30:24] spi_rxd_3 — The register value indicates the selected GPIO number + 2 (GPIO2 - GPIO63, GPIO0 and GPIO1 are not available) for the input signal.
  [22:16] spi_fssin_3 — The register value indicates the selected GPIO number + 2 (GPIO2 - GPIO63, GPIO0 and GPIO1 are not available) for the input signal.
  [14:8] spi_clkin_3 — The register value indicates the selected GPIO number + 2 (GPIO2 - GPIO63, GPIO0 and GPIO1 are not available) for the input signal.
  [6:0] uart_sin_3 — The register value indicates the selected GPIO number + 2 (GPIO2 - GPIO63, GPIO0 and GPIO1 are not available) for the input signal.
0xC8 gpi_18 reset 0x2E310000 — SYS IOMUX CFG SAIF SYSCFG FMUX GPIO GPI 72 - The register can be used to configure the selected GPIO connector number for input signals. The signal name is indicated in the "Name" column of the following table per StarFive naming conventions. For example, name "u0_WAVE511_i_uart_rxsin_cfg" indicates the corresponding input signal is "u0_WAVE511.i_uart_rxsin". See GPIO Input Signals (on page 107) for a complete list of the input GPIO signals.
  [30:24] uart_sin_4 — The register value indicates the selected GPIO number + 2 (GPIO2 - GPIO63, GPIO0 and GPIO1 are not available) for the input signal.
  [22:16] uart_cts_4 — The register value indicates the selected GPIO number + 2 (GPIO2 - GPIO63, GPIO0 and GPIO1 are not available) for the input signal.
  [14:8] i2c_data_4 — The register value indicates the selected GPIO number + 2 (GPIO2 - GPIO63, GPIO0 and GPIO1 are not available) for the input signal.
  [6:0] i2c_clk_4 — The register value indicates the selected GPIO number + 2 (GPIO2 - GPIO63, GPIO0 and GPIO1 are not available) for the input signal.
0xCC gpi_19 reset 0x403E3F — SYS IOMUX CFG SAIF SYSCFG FMUX GPIO GPI 76 - The register can be used to configure the selected GPIO connector number for input signals. The signal name is indicated in the "Name" column of the following table per StarFive naming conventions. For example, name "u0_WAVE511_i_uart_rxsin_cfg" indicates the corresponding input signal is "u0_WAVE511.i_uart_rxsin". See GPIO Input Signals (on page 107) for a complete list of the input GPIO signals.
  [30:24] i2c_clk_5 — The register value indicates the selected GPIO number + 2 (GPIO2 - GPIO63, GPIO0 and GPIO1 are not available) for the input signal.
  [22:16] spi_rxd_4 — The register value indicates the selected GPIO number + 2 (GPIO2 - GPIO63, GPIO0 and GPIO1 are not available) for the input signal.
  [14:8] spi_fssin_4 — The register value indicates the selected GPIO number + 2 (GPIO2 - GPIO63, GPIO0 and GPIO1 are not available) for the input signal.
  [6:0] spi_clkin_4 — The register value indicates the selected GPIO number + 2 (GPIO2 - GPIO63, GPIO0 and GPIO1 are not available) for the input signal.
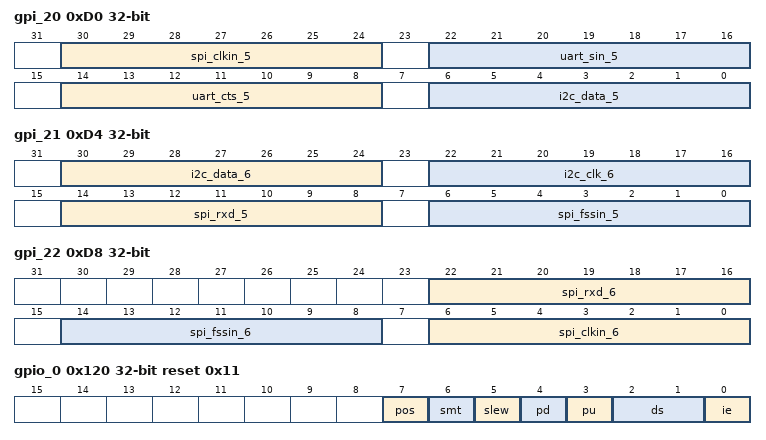
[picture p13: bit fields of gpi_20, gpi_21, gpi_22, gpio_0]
0xD0 gpi_20 — SYS IOMUX CFG SAIF SYSCFG FMUX GPIO GPI 80 - The register can be used to configure the selected GPIO connector number for input signals. The signal name is indicated in the "Name" column of the following table per StarFive naming conventions. For example, name "u0_WAVE511_i_uart_rxsin_cfg" indicates the corresponding input signal is "u0_WAVE511.i_uart_rxsin". See GPIO Input Signals (on page 107) for a complete list of the input GPIO signals.
  [30:24] spi_clkin_5 — The register value indicates the selected GPIO number + 2 (GPIO2 - GPIO63, GPIO0 and GPIO1 are not available) for the input signal.
  [22:16] uart_sin_5 — The register value indicates the selected GPIO number + 2 (GPIO2 - GPIO63, GPIO0 and GPIO1 are not available) for the input signal.
  [14:8] uart_cts_5 — The register value indicates the selected GPIO number + 2 (GPIO2 - GPIO63, GPIO0 and GPIO1 are not available) for the input signal.
  [6:0] i2c_data_5 — The register value indicates the selected GPIO number + 2 (GPIO2 - GPIO63, GPIO0 and GPIO1 are not available) for the input signal.
0xD4 gpi_21 — SYS IOMUX CFG SAIF SYSCFG FMUX GPIO GPI 84 - The register can be used to configure the selected GPIO connector number for input signals. The signal name is indicated in the "Name" column of the following table per StarFive naming conventions. For example, name "u0_WAVE511_i_uart_rxsin_cfg" indicates the corresponding input signal is "u0_WAVE511.i_uart_rxsin". See GPIO Input Signals (on page 107) for a complete list of the input GPIO signals.
  [30:24] i2c_data_6 — The register value indicates the selected GPIO number + 2 (GPIO2 - GPIO63, GPIO0 and GPIO1 are not available) for the input signal.
  [22:16] i2c_clk_6 — The register value indicates the selected GPIO number + 2 (GPIO2 - GPIO63, GPIO0 and GPIO1 are not available) for the input signal.
  [14:8] spi_rxd_5 — The register value indicates the selected GPIO number + 2 (GPIO2 - GPIO63, GPIO0 and GPIO1 are not available) for the input signal.
  [6:0] spi_fssin_5 — The register value indicates the selected GPIO number + 2 (GPIO2 - GPIO63, GPIO0 and GPIO1 are not available) for the input signal.
0xD8 gpi_22 — SYS IOMUX CFG SAIF SYSCFG FMUX GPIO GPI 88 - The register can be used to configure the selected GPIO connector number for input signals. The signal name is indicated in the "Name" column of the following table per StarFive naming conventions. For example, name "u0_WAVE511_i_uart_rxsin_cfg" indicates the corresponding input signal is "u0_WAVE511.i_uart_rxsin". See GPIO Input Signals (on page 107) for a complete list of the input GPIO signals.
  [22:16] spi_rxd_6 — The register value indicates the selected GPIO number + 2 (GPIO2 - GPIO63, GPIO0 and GPIO1 are not available) for the input signal.
  [14:8] spi_fssin_6 — The register value indicates the selected GPIO number + 2 (GPIO2 - GPIO63, GPIO0 and GPIO1 are not available) for the input signal.
  [6:0] spi_clkin_6 — The register value indicates the selected GPIO number + 2 (GPIO2 - GPIO63, GPIO0 and GPIO1 are not available) for the input signal.
0xDC ioirq_0 — Enable GPIO IRQ function
  [0] gpen_0 — 1: Enable, 0: Disable
0xE0 ioirq_1 — SYS IOMUX CFGSAIF SYSCFG IOIRQ 224: GPIO Interrupt Edge Trigger Selector
  [31:0] is_0 — 1: Edge trigger, 0: Level trigger
0xE4 ioirq_2 — SYS IOMUX CFGSAIF SYSCFG IOIRQ 228: GPIO Interrupt Edge Trigger Selector
  [31:0] is_1 — 1: Edge trigger, 0: Level trigger
0xE8 ioirq_3 — SYS IOMUX CFGSAIF SYSCFG IOIRQ 232: GPIO Interrupt Clear
  [31:0] ic_0 — 1: Do not clear the register, 0: Clear the register
0xEC ioirq_4 — SYS IOMUX CFGSAIF SYSCFG IOIRQ 236: GPIO Interrupt Clear
  [31:0] ic_1 — 1: Do not clear the register, 0: Clear the register
0xF0 ioirq_5 — SYS IOMUX CFGSAIF SYSCFG IOIRQ 240: GPIO Interrupt Both Edge Trigger Selector
  [31:0] ibe_0 — 1: Trigger on both edges, 0: Trigger on a single edge
0xF4 ioirq_6 — SYS IOMUX CFGSAIF SYSCFG IOIRQ 244: GPIO Interrupt Both Edge Trigger Selector
  [31:0] ibe_1 — 1: Trigger on both edges, 0: Trigger on a single edge
0xF8 ioirq_7 — SYS IOMUX CFGSAIF SYSCFG IOIRQ 248: GPIO Interrupt Edge Value
  [31:0] iev_0 — 1: Positive/Low, 0: Negative/High
0xFC ioirq_8 — SYS IOMUX CFGSAIF SYSCFG IOIRQ 252: GPIO Interrupt Edge Value
  [31:0] iev_1 — 1: Positive/Low, 0: Negative/High
0x100 ioirq_9 — SYS IOMUX CFGSAIF SYSCFG IOIRQ 256: GPIO Interrupt Edge Mask Selector
  [31:0] ie_0 — 1: Unmask, 0: Mask
0x104 ioirq_10 — SYS IOMUX CFGSAIF SYSCFG IOIRQ 260: GPIO Interrupt Edge Mask Selector
  [31:0] ie_1 — 1: Unmask, 0: Mask
0x108 ioirq_11 — SYS IOMUX CFGSAIF SYSCFG IOIRQ 264: GPIO Register Interrupt Status
  [31:0] ris_0 ro — Status of the edge trigger. The register can be cleared by writing gpio ic
0x10C ioirq_12 — SYS IOMUX CFGSAIF SYSCFG IOIRQ 268: GPIO Register Interrupt Status
  [31:0] ris_1 ro — Status of the edge trigger. The register can be cleared by writing gpio ic
0x110 ioirq_13 — SYS IOMUX CFGSAIF SYSCFG IOIRQ 272: GPIO Masked Interrupt Status
  [31:0] mis_0 ro — The masked GPIO IRQ status
0x114 ioirq_14 — SYS IOMUX CFGSAIF SYSCFG IOIRQ 276: GPIO Masked Interrupt Status
  [31:0] mis_1 ro — The masked GPIO IRQ status
0x118 ioirq_15 — SYS IOMUX CFGSAIF SYSCFG IOIRQ 280: GPIO Synchronization Status
  [31:0] in_sync2_0 ro — Status of the gpio_in after synchronization
0x11C ioirq_16 — SYS IOMUX CFGSAIF SYSCFG IOIRQ 284: GPIO Synchronization Status
  [31:0] in_sync2_1 ro — Status of the gpio_in after synchronization
0x120 gpio_0 reset 0x11 — SYS IOMUX CFG SAIF SYSCFG PADCFG 288: GPIO_0
  [7] pos — Power-on-Start (POS) enabler - 1: Enable active pull down for loss of core power, 0: Active pull-down capability disabled
  [6] smt — Active high Schmitt (SMT) trigger selector - 0: No hysteresis, 1: Schmitt trigger ebabled
  [5] slew — Slew Rate Control - 0: Slow (Half frequency), 1: Fast
  [4] pd — Pull-Down (PD) settings - 1: Yes, 0: No
  [3] pu — Pull-Up (PU) settings - 1: Yes, 0: No
  [2:1] ds — Output Drive Strength (DS) - 00: The rated drive strength is 2 mA, 01: The rated drive strength is 4 mA, 10: The rated drive strength is 8 mA, 11: The rated drive strength is 12 mA
  [0] ie — Input Enable (IE) Controller - 1: Enable the receiver, 0: Disable the receiver
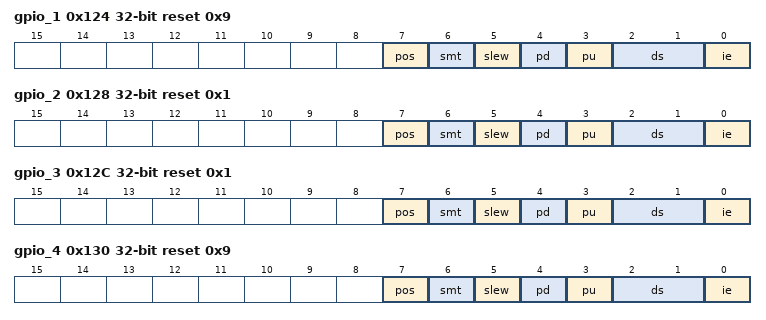
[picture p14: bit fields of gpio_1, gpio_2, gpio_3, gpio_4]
0x124 gpio_1 reset 0x9 — SYS IOMUX CFG SAIF SYSCFG PADCFG 292: GPIO_1
  fields as gpio_0
0x128 gpio_2 reset 0x1 — SYS IOMUX CFG SAIF SYSCFG PADCFG 296: GPIO_2
  fields as gpio_0
0x12C gpio_3 reset 0x1 — SYS IOMUX CFG SAIF SYSCFG PADCFG 300: GPIO_3
  fields as gpio_0
0x130 gpio_4 reset 0x9 — SYS IOMUX CFG SAIF SYSCFG PADCFG 304: GPIO_4
  fields as gpio_0
0x134 gpio_5 — SYS IOMUX CFG SAIF SYSCFG PADCFG 308: GPIO_5
  fields as gpio_0
0x138 gpio_6 reset 0x9 — SYS IOMUX CFG SAIF SYSCFG PADCFG 312: GPIO_6
  fields as gpio_0
0x13C gpio_7 reset 0x1 — SYS IOMUX CFG SAIF SYSCFG PADCFG 316: GPIO_7
  fields as gpio_0
0x140 gpio_8 reset 0x1 — SYS IOMUX CFG SAIF SYSCFG PADCFG 320: GPIO_8
  fields as gpio_0
0x144 gpio_9 reset 0x9 — SYS IOMUX CFG SAIF SYSCFG PADCFG 324: GPIO_9
  fields as gpio_0
0x148 gpio_10 reset 0x1 — SYS IOMUX CFG SAIF SYSCFG PADCFG 328: GPIO_10
  fields as gpio_0
0x14C gpio_11 reset 0x1 — SYS IOMUX CFG SAIF SYSCFG PADCFG 332: GPIO_11
  fields as gpio_0
0x150 gpio_12 reset 0x9 — SYS IOMUX CFG SAIF SYSCFG PADCFG 336: GPIO_12
  fields as gpio_0
0x154 gpio_13 reset 0x9 — SYS IOMUX CFG SAIF SYSCFG PADCFG 340: GPIO_13
  fields as gpio_0
{0x120+4i} gpio_{i} reset 0x1 (i=14..17) — SYS IOMUX CFG SAIF SYSCFG PADCFG {4i+288}: GPIO_{i}
  fields as gpio_0
0x168 gpio_18 reset 0x9 — SYS IOMUX CFG SAIF SYSCFG PADCFG 360: GPIO_18
  fields as gpio_0
0x16C gpio_19 reset 0x9 — SYS IOMUX CFG SAIF SYSCFG PADCFG 364: GPIO_19
  fields as gpio_0
{0x120+4i} gpio_{i} reset 0x1 (i=20..32) — SYS IOMUX CFG SAIF SYSCFG PADCFG {4i+288}: GPIO_{i}
  fields as gpio_0
0x1A4 gpio_33 — SYS IOMUX CFG SAIF SYSCFG PADCFG 420: GPIO_33
  fields as gpio_0
0x1A8 gpio_34 reset 0x1 — SYS IOMUX CFG SAIF SYSCFG PADCFG 424: GPIO_34
  fields as gpio_0
0x1AC gpio_35 reset 0x11 — SYS IOMUX CFG SAIF SYSCFG PADCFG 428: GPIO_35
  fields as gpio_0
{0x120+4i} gpio_{i} reset 0x9 (i=36..48) — SYS IOMUX CFG SAIF SYSCFG PADCFG {4i+288}: GPIO_{i}
  fields as gpio_0
{0x120+4i} gpio_{i} reset 0x1 (i=49..51) — SYS IOMUX CFG SAIF SYSCFG PADCFG {4i+288}: GPIO_{i}
  fields as gpio_0
0x1F0 gpio_52 reset 0x9 — SYS IOMUX CFG SAIF SYSCFG PADCFG 496: GPIO_52
  fields as gpio_0
{0x120+4i} gpio_{i} reset 0x1 (i=53..55) — SYS IOMUX CFG SAIF SYSCFG PADCFG {4i+288}: GPIO_{i}
  fields as gpio_0
0x200 gpio_56 reset 0x9 — SYS IOMUX CFG SAIF SYSCFG PADCFG 512: GPIO_56
  fields as gpio_0
{0x120+4i} gpio_{i} reset 0x1 (i=57..59) — SYS IOMUX CFG SAIF SYSCFG PADCFG {4i+288}: GPIO_{i}
  fields as gpio_0
0x210 gpio_60 reset 0x9 — SYS IOMUX CFG SAIF SYSCFG PADCFG 528: GPIO_60
  fields as gpio_0
{0x120+4i} gpio_{i} reset 0x1 (i=61..63) — SYS IOMUX CFG SAIF SYSCFG PADCFG {4i+288}: GPIO_{i}
  fields as gpio_0
0x220 sd0_clk reset 0x1 — SYS IOMUX CFG SAIF SYSCFG PADCFG 544: SD0_CLK
  fields as gpio_0
0x224 sd0_cmd reset 0x9 — SYS IOMUX CFG SAIF SYSCFG PADCFG 548: SD0_CMD
  fields as gpio_0
0x228 sd0_data_0 reset 0x1 — SYS IOMUX CFG SAIF SYSCFG PADCFG 552: SD0_DATA_0
  fields as gpio_0
0x22C sd0_data_1 reset 0x1 — SYS IOMUX CFG SAIF SYSCFG PADCFG 556: SD0_DATA_1
  fields as gpio_0
0x230 sd0_data_2 reset 0x9 — SYS IOMUX CFG SAIF SYSCFG PADCFG 560: SD0_DATA_2
  fields as gpio_0
0x234 sd0_data_3 reset 0x9 — SYS IOMUX CFG SAIF SYSCFG PADCFG 564: SD0_DATA_3
  fields as gpio_0
{0x228+4i} sd0_data_{i} reset 0x1 (i=4..7) — SYS IOMUX CFG SAIF SYSCFG PADCFG {4i+552}: SD0_DATA_{i}
  fields as gpio_0
0x248 sd0_strb — SYS IOMUX CFG SAIF SYSCFG PADCFG 584: SD0_STRB
  fields as gpio_0
0x24C gmac1_mdc reset 0x2 — GPIO GMAC1 MDC Pad Configuration
  [1:0] cfg
0x250 gmac1_mdio reset 0x2 — GPIO GMAC1 MDIO Pad Configuration
  [1:0] cfg
{0x254+4i} gmac1_rxd_{i} reset 0x2 (i=0..3) — GPIO GMAC1 RXD_{i} Pad Configuration
  [1:0] cfg
0x264 gmac1_rxdv reset 0x2 — GPIO GMAC1 RXDV Pad Configuration
  [1:0] cfg
0x268 gmac1_rxc reset 0x2 — GPIO GMAC1 RXC Pad Configuration
  [1:0] cfg
{0x26C+4i} gmac1_txd_{i} reset 0x2 (i=0..3) — GPIO GMAC1 TXD_{i} Pad Configuration
  [1:0] cfg
0x27C gmac1_txen reset 0x2 — GPIO GMAC1 TXEN Pad Configuration
  [1:0] cfg
0x280 gmac1_txc reset 0x2 — GPIO GMAC1 TXC Pad Configuration
  [1:0] cfg
0x284 qspi_sclk reset 0x8 — SYS IOMUX CFG SAIF SYSCFG PADCFG 644: QSPI_SCLK
  fields as gpio_0
0x288 qspi_csn_0 reset 0x1 — SYS IOMUX CFG SAIF SYSCFG PADCFG 648: QSPI_CSN_0
  fields as gpio_0
{0x28C+4i} qspi_data_{i} reset 0x1 (i=0..2) — SYS IOMUX CFG SAIF SYSCFG PADCFG {4i+652}: QSPI_DATA_{i}
  fields as gpio_0
0x298 qspi_data_3 reset 0x9 — SYS IOMUX CFG SAIF SYSCFG PADCFG 664: QSPI_DATA_3
  fields as gpio_0
0x29C func_sel_0 — SYS IOMUX CFG SAIF SYSCFG 668
  [3n-26:3n-28] pad_gpio_{n} (n=10..19) — GPIO function selector: * Function 0: See Function Description no page 84 for more information, * Function 1: See Full Multiplexing for more information, * Function 2: See Function 2 for more information, * Function 3: See Function 3 for more information
  [1:0] pad_gmac1_rxc — Function selector of GMAC1_RXC: * Function 0: u0_sys_crg.clk_gmac1_rgmii_rx, * Function 1: u0_sys_crg.clk_gmac1_rmii_ref, * Function 2: None, * Function 3: None
0x2A0 func_sel_1 — SYS IOMUX CFG SAIF SYSCFG 672
  [3n-58:3n-60] pad_gpio_{n} (n=20..29) — GPIO function selector: * Function 0: See Function Description no page 84 for more information, * Function 1: See Full Multiplexing for more information, * Function 2: See Function 2 for more information, * Function 3: See Function 3 for more information
0x2A4 func_sel_2 — SYS IOMUX CFG SAIF SYSCFG 676
  [3n-88:3n-90] pad_gpio_{n} (n=30..40) — GPIO function selector: * Function 0: See Function Description no page 84 for more information, * Function 1: See Full Multiplexing for more information, * Function 2: See Function 2 for more information, * Function 3: See Function 3 for more information
0x2A8 func_sel_3 — SYS IOMUX CFG SAIF SYSCFG 680
  [3n-121:3n-123] pad_gpio_{n} (n=41..51) — GPIO function selector: * Function 0: See Function Description no page 84 for more information, * Function 1: See Full Multiplexing for more information, * Function 2: See Function 2 for more information, * Function 3: See Function 3 for more information
0x2AC func_sel_4 — SYS IOMUX CFG SAIF SYSCFG 684
  [3n-154:3n-156] pad_gpio_{n} (n=56..62) — GPIO function selector: * Function 0: See Function Description no page 84 for more information, * Function 1: See Full Multiplexing for more information, * Function 2: See Function 2 for more information, * Function 3: See Function 3 for more information
  [31:30] pad_gpio63 — GPIO function selector: * Function 0: See Function Description no page 84 for more information, * Function 1: See Full Multiplexing for more information, * Function 2: See Function 2 for more information, * Function 3: See Function 3 for more information
  [5:4] pad_gpio_54 — GPIO function selector: * Function 0: See Function Description no page 84 for more information, * Function 1: See Full Multiplexing for more information, * Function 2: See Function 2 for more information, * Function 3: See Function 3 for more information
  [3:2] pad_gpio_53 — GPIO function selector: * Function 0: See Function Description no page 84 for more information, * Function 1: See Full Multiplexing for more information, * Function 2: See Function 2 for more information, * Function 3: See Function 3 for more information
  [1:0] pad_gpio_52 — GPIO function selector: * Function 0: See Function Description no page 84 for more information, * Function 1: See Full Multiplexing for more information, * Function 2: See Function 2 for more information, * Function 3: See Function 3 for more information
0x2B0 func_sel_5 — SYS IOMUX CFG SAIF SYSCFG 688
  [3n+19:3n+17] vin_dvp_data_{n} (n=1..4) — Function Selector of DVP_DATA[idx], see Function 2 for more information
  [19:17] vin_dvp_data_11 — Function Selector of DVP_DATA[idx], see Function 2 for more information
  [16:14] vin_dvp_data_10 — Function Selector of DVP_DATA[idx], see Function 2 for more information
  [13:11] vin_dvp_data_0 — Function Selector of DVP_DATA[idx], see Function 2 for more information
  [11:9] pad_gpio_9 — GPIO function selector: * Function 0: See Function Description no page 84 for more information, * Function 1: See Full Multiplexing for more information, * Function 2: See Function 2 for more information, * Function 3: See Function 3 for more information
  [8:6] pad_gpio_8 — GPIO function selector: * Function 0: See Function Description no page 84 for more information, * Function 1: See Full Multiplexing for more information, * Function 2: See Function 2 for more information, * Function 3: See Function 3 for more information
  [5:3] pad_gpio_7 — GPIO function selector: * Function 0: See Function Description no page 84 for more information, * Function 1: See Full Multiplexing for more information, * Function 2: See Function 2 for more information, * Function 3: See Function 3 for more information
  [1:0] pad_gpio_6 — GPIO function selector: * Function 0: See Function Description no page 84 for more information, * Function 1: See Full Multiplexing for more information, * Function 2: See Function 2 for more information, * Function 3: See Function 3 for more information
0x2B4 func_sel_6 — SYS IOMUX CFG SAIF SYSCFG 692
  [23:21] dvp_clk — Function Selector of DVP_CLK, see Function 2 for more information
  [20:18] vin_dvp_vvalid — Function Selector of DVP_VSYNC, see Function 2 for more information
  [17:15] vin_dvp_hvalid — Function Selector of DVP_HSYNC, see Function 2 for more information
  [3n-13:3n-15] vin_dvp_data_{n} (n=5..9) — Function Selector of DVP_DATA[idx], see Function 2 for more information
